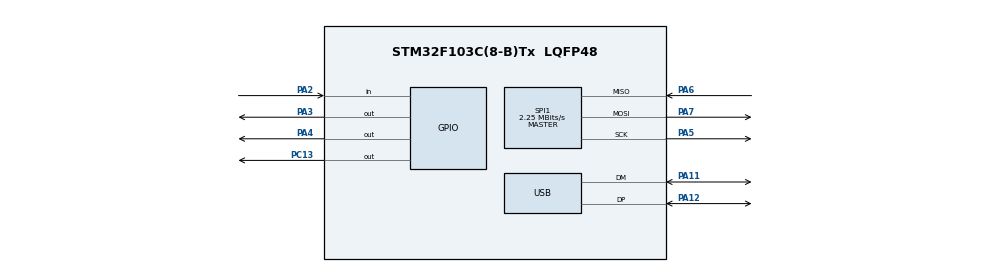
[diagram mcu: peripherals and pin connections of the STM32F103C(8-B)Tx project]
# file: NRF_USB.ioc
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Mcu.Family=STM32F1
Mcu.Name=STM32F103C(8-B)Tx
Mcu.Package=LQFP48
NVIC.PriorityGroup=NVIC_PRIORITYGROUP_4
NVIC.TIM2_IRQn=true\:0\:0\:false\:false\:true\:true\:true
NVIC.USB_LP_CAN1_RX0_IRQn=true\:0\:0\:false\:false\:true\:false\:true
PA11.Mode=Device
PA11.Signal=USB_DM
PA12.Mode=Device
PA12.Signal=USB_DP
PA13.Mode=Serial_Wire
PA13.Signal=SYS_JTMS-SWDIO
PA14.Mode=Serial_Wire
PA14.Signal=SYS_JTCK-SWCLK
PA2.Signal=GPIO_Input
PA3.Signal=GPIO_Output
PA4.Signal=GPIO_Output
PA5.Mode=Full_Duplex_Master
PA5.Signal=SPI1_SCK
PA6.Mode=Full_Duplex_Master
PA6.Signal=SPI1_MISO
PA7.Mode=Full_Duplex_Master
PA7.Signal=SPI1_MOSI
PC13-TAMPER-RTC.Signal=GPIO_Output
PC14-OSC32_IN.Mode=LSE-External-Oscillator
PC14-OSC32_IN.Signal=RCC_OSC32_IN
PC15-OSC32_OUT.Mode=LSE-External-Oscillator
PC15-OSC32_OUT.Signal=RCC_OSC32_OUT
PD0-OSC_IN.Mode=HSE-External-Oscillator
PD0-OSC_IN.Signal=RCC_OSC_IN
PD1-OSC_OUT.Mode=HSE-External-Oscillator
PD1-OSC_OUT.Signal=RCC_OSC_OUT
ProjectManager.HeapSize=0x400
ProjectManager.StackSize=0x800
ProjectManager.TargetToolchain=MDK-ARM V5.27
RCC.AHBFreq_Value=72000000
RCC.APB1CLKDivider=RCC_HCLK_DIV2
RCC.APB1Freq_Value=36000000
RCC.APB1TimFreq_Value=72000000
RCC.APB2Freq_Value=72000000
RCC.APB2TimFreq_Value=72000000
RCC.HCLKFreq_Value=72000000
RCC.PLLMUL=RCC_PLL_MUL9
RCC.PREFETCH_ENABLE=1
RCC.RTCClockSelection=RCC_RTCCLKSOURCE_HSE_DIV128
RCC.SYSCLKFreq_VALUE=72000000
RCC.SYSCLKSource=RCC_SYSCLKSOURCE_PLLCLK
RCC.USBFreq_Value=48000000
RCC.USBPrescaler=RCC_USBCLKSOURCE_PLL_DIV1_5
SPI1.BaudRatePrescaler=SPI_BAUDRATEPRESCALER_32
SPI1.CalculateBaudRate=2.25 MBits/s
SPI1.Direction=SPI_DIRECTION_2LINES
SPI1.Mode=SPI_MODE_MASTER
SPI1.VirtualType=VM_MASTER
TIM2.Period=4000
TIM2.Prescaler=35999
TIM2.TIM_MasterOutputTrigger=TIM_TRGO_UPDATE
USB_DEVICE.CLASS_NAME_FS=CDC
USB_DEVICE.VirtualMode=Cdc
USB_DEVICE.VirtualModeFS=Cdc_FS
VP_RTC_VS_RTC_Activate.Mode=RTC_Enabled
VP_TIM2_VS_ClockSourceINT.Mode=Internal
VP_USB_DEVICE_VS_USB_DEVICE_CDC_FS.Mode=CDC_FS
board=custom

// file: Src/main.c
/* USER CODE BEGIN Header */
/**
  ******************************************************************************
  * @file           : main.c
  * @brief          : Main program body
  ******************************************************************************
  * @attention
  *
  * <h2><center>&copy; Copyright (c) 2020 STMicroelectronics.
  * All rights reserved.</center></h2>
  *
  * This software component is licensed by ST under Ultimate Liberty license
  * SLA0044, the "License"; You may not use this file except in compliance with
  * the License. You may obtain a copy of the License at:
  *                             www.st.com/SLA0044
  *
  ******************************************************************************
  */
/* USER CODE END Header */

#include "main.h"
#include "rtc.h"
#include "spi.h"
#include "tim.h"
#include "usb_device.h"
#include "gpio.h"

/* USER CODE BEGIN Includes */
#include "NRF24.h"
#include <string.h>
#include "usbd_cdc_if.h"

/* USER CODE END Includes */

/* USER CODE BEGIN PV */
	char str1[150]={0}; //for test channel
//	uint16_t buf1[20] = {0}; //for transmit to air
//	char str_tx[21] = {0}; // to transmit to USB
//	char str_rx[21]; // to recieve from USB
	uint8_t recBufLen = 0;
/* USER CODE END PV */

void SystemClock_Config(void);
uint8_t NRF24L01_Send(uint8_t *pBuf);
void NRF24L01_Receive(void);

int main(void)
{
  /* USER CODE BEGIN 1 */
//////uint8_t dt_reg=0; for testing a channel
	//uint8_t retr_cnt; // for counter
	//uint16_t i = 1, retr_cnt_full; // the same
//	uint8_t i = 0; // for FOR
	uint8_t dt;
  /* USER CODE END 1 */

  /* MCU Configuration--------------------------------------------------------*/

  /* Reset of all peripherals, Initializes the Flash interface and the Systick. */
  HAL_Init();

  /* Configure the system clock */
  SystemClock_Config();

  /* Initialize all configured peripherals */
  MX_GPIO_Init();
  MX_RTC_Init();
  MX_USB_DEVICE_Init();
  MX_TIM2_Init();
  MX_SPI1_Init();
  /* USER CODE BEGIN 2 */
	HAL_Delay(200);
	NRF24_ini();
//							sprintf(str_tx,"USB Transmit\r\n");

  /* USER CODE END 2 */

  /* Infinite loop */
  /* USER CODE BEGIN WHILE */
  while (1)
  {
		if(recBufLen > 0)
		{
//HAL_Delay(250);
				dt = NRF24L01_Send((uint8_t*)UserRxBufferFS);
				CDC_Transmit_FS((uint8_t*)UserRxBufferFS, recBufLen);
				recBufLen = 0;
		}
//		int i = 1;
//		memcpy(str_tx,(char*)&UserRxBufferFS,64);
//		CDC_Transmit_FS((unsigned char*)str_tx, strlen(str_tx));
//		for(i = 0; i <= 63; i++)
//		{
//		UserRxBufferFS[i] = 0;
//		}
				//for (i = 0; i < 63; i++) {free((char*)&UserRxBufferFS[i]);}

//                HAL_Delay(500);
//////		HAL_Delay(1000);
//////		char string[] = "12345678987654321sdfgjdynujydfghnyrfgdf";
//////		memcpy(buf1,(uint8_t*)&string,30);
//		if(retr_cnt_full>999) retr_cnt_full=999;
//		memcpy(buf1+2,(uint8_t*)&retr_cnt_full,2);
//////		dt = NRF24L01_Send((uint8_t*)buf1);
//////		CDC_Transmit_FS((uint8_t*)string,strlen((const char*)string));
//    LED_TGL;

////////		retr_cnt = dt & 0xF;
////////		i++;
////////		retr_cnt_full += retr_cnt;
////////		if(i>=999) i=1;
////  dt_reg = NRF24_ReadReg(CONFIG);
////  sprintf(str1,"CONFIG: 0x%02Xrn",dt_reg);
////CDC_Transmit_FS((uint8_t*)str1,strlen(str1));
////  dt_reg = NRF24_ReadReg(EN_AA);
////  sprintf(str1,"EN_AA: 0x%02Xrn",dt_reg);
////CDC_Transmit_FS((uint8_t*)str1,strlen(str1));
////  dt_reg = NRF24_ReadReg(EN_RXADDR);
////  sprintf(str1,"EN_RXADDR: 0x%02Xrn",dt_reg);
////CDC_Transmit_FS((uint8_t*)str1,strlen(str1));
////  dt_reg = NRF24_ReadReg(STATUS);
////  sprintf(str1,"STATUS: 0x%02Xrn",dt_reg);
////CDC_Transmit_FS((uint8_t*)str1,strlen(str1));
////  dt_reg = NRF24_ReadReg(RF_SETUP);
////  sprintf(str1,"RF_SETUP: 0x%02Xrn",dt_reg);
////CDC_Transmit_FS((uint8_t*)str1,strlen(str1));
////  NRF24_Read_Buf(TX_ADDR,buf1,3);
////  sprintf(str1,"TX_ADDR: 0x%02X, 0x%02X, 0x%02Xrn",buf1[0],buf1[1],buf1[2]);
////CDC_Transmit_FS((uint8_t*)str1,strlen(str1));
////  NRF24_Read_Buf(RX_ADDR_P0,buf1,3);
////  sprintf(str1,"RX_ADDR: 0x%02X, 0x%02X, 0x%02Xrn",buf1[0],buf1[1],buf1[2]);
////CDC_Transmit_FS((uint8_t*)str1,strlen(str1));
    /* USER CODE END WHILE */

    /* USER CODE BEGIN 3 */
//		NRF24L01_Receive();
  }
  /* USER CODE END 3 */
}

void SystemClock_Config(void)
{
  LL_FLASH_SetLatency(LL_FLASH_LATENCY_2);

   if(LL_FLASH_GetLatency() != LL_FLASH_LATENCY_2)
  {
    Error_Handler();
  }
  LL_RCC_HSE_Enable();

   /* Wait till HSE is ready */
  while(LL_RCC_HSE_IsReady() != 1)
  {

  }
  LL_PWR_EnableBkUpAccess();
  LL_RCC_ForceBackupDomainReset();
  LL_RCC_ReleaseBackupDomainReset();
  LL_RCC_SetRTCClockSource(LL_RCC_RTC_CLKSOURCE_HSE_DIV128);
  LL_RCC_EnableRTC();
  LL_RCC_PLL_ConfigDomain_SYS(LL_RCC_PLLSOURCE_HSE_DIV_1, LL_RCC_PLL_MUL_9);
  LL_RCC_PLL_Enable();

   /* Wait till PLL is ready */
  while(LL_RCC_PLL_IsReady() != 1)
  {

  }
  LL_RCC_SetAHBPrescaler(LL_RCC_SYSCLK_DIV_1);
  LL_RCC_SetAPB1Prescaler(LL_RCC_APB1_DIV_2);
  LL_RCC_SetAPB2Prescaler(LL_RCC_APB2_DIV_1);
  LL_RCC_SetSysClkSource(LL_RCC_SYS_CLKSOURCE_PLL);

   /* Wait till System clock is ready */
  while(LL_RCC_GetSysClkSource() != LL_RCC_SYS_CLKSOURCE_STATUS_PLL)
  {

  }
  LL_SetSystemCoreClock(72000000);

   /* Update the time base */
  if (HAL_InitTick (TICK_INT_PRIORITY) != HAL_OK)
  {
    Error_Handler();
  };
  LL_RCC_SetUSBClockSource(LL_RCC_USB_CLKSOURCE_PLL_DIV_1_5);
}

void Error_Handler(void)
{
}

/************************ (C) COPYRIGHT STMicroelectronics *****END OF FILE****/
